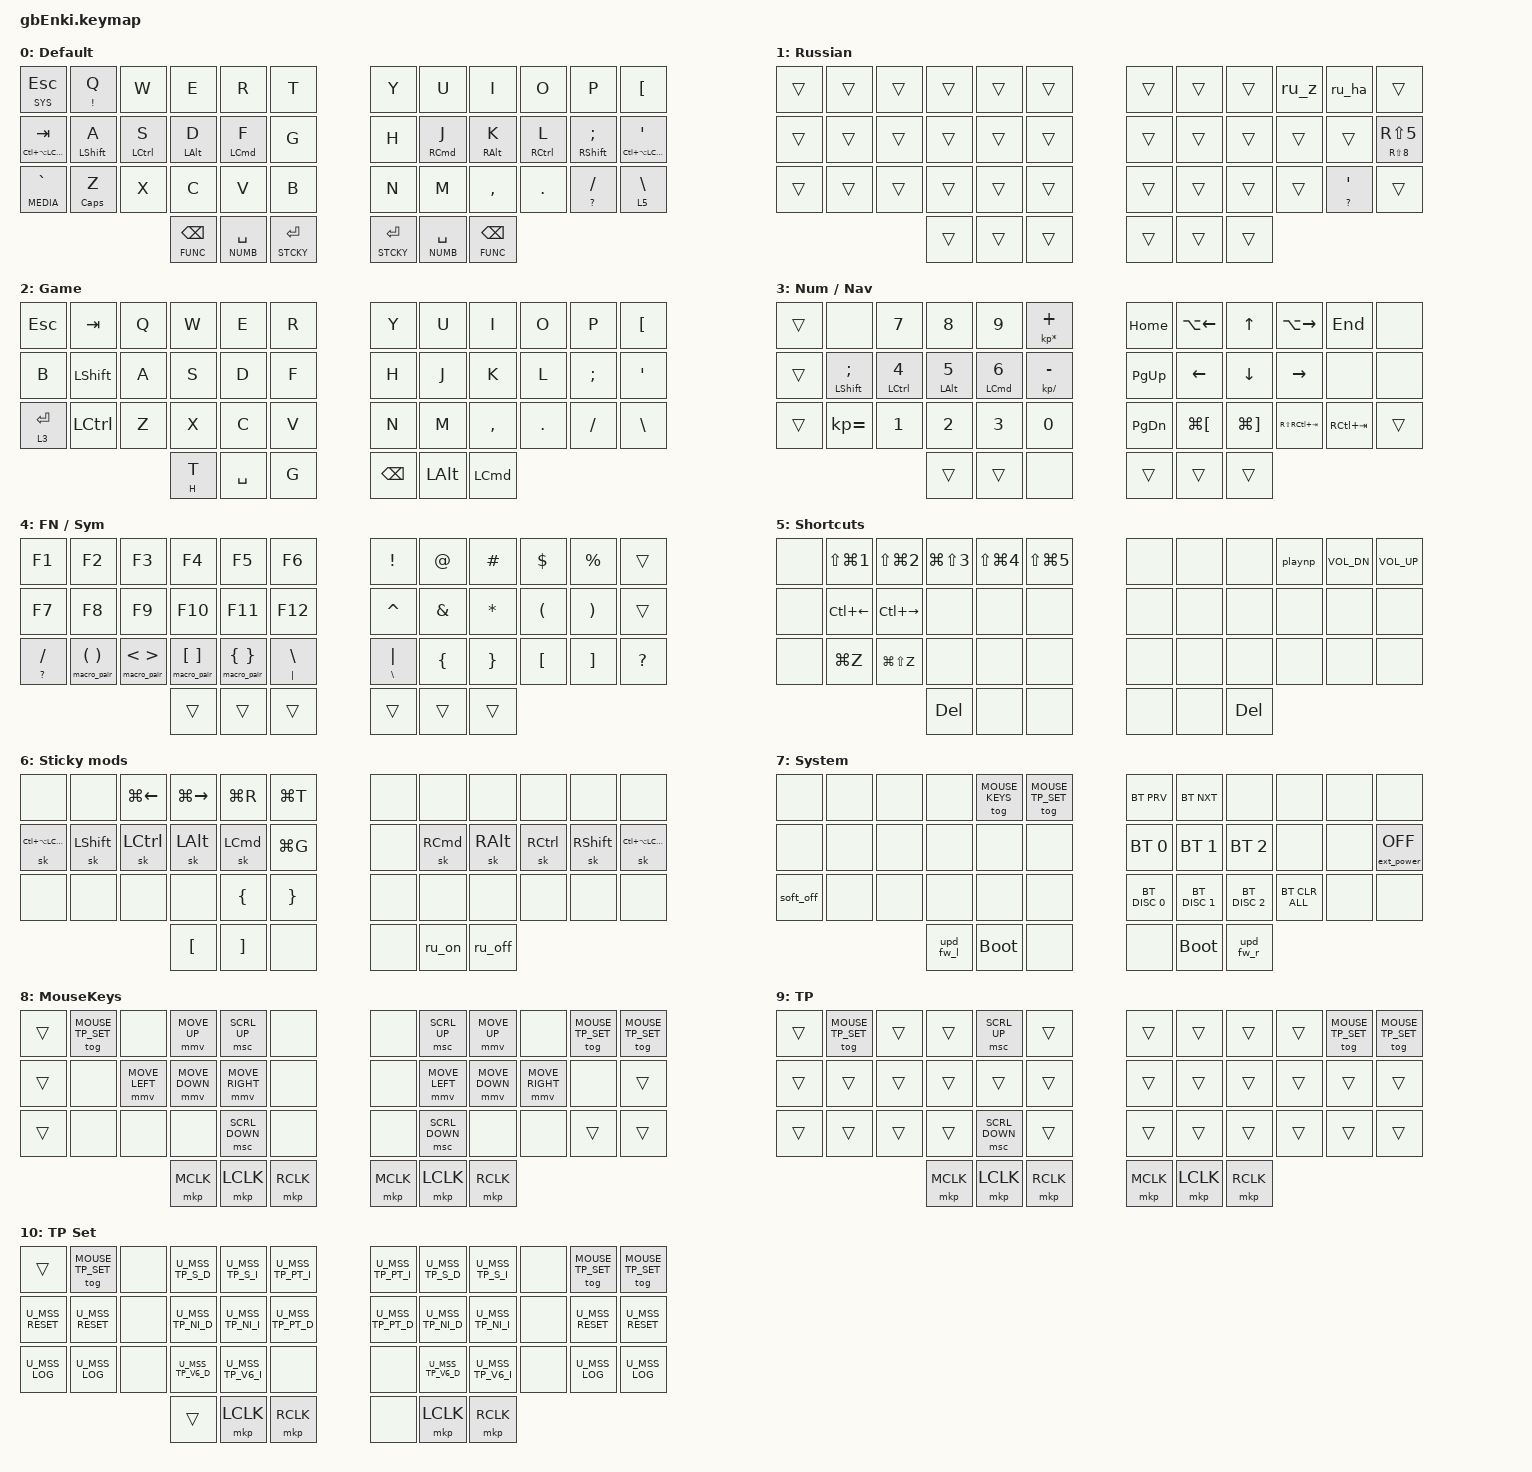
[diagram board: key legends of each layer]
/*
 * Copyright (c) 2020 The ZMK Contributors
 *
 * SPDX-License-Identifier: MIT
 */

// #include <behaviors/num_word.dtsi>
#include <behaviors.dtsi>
#include <dt-bindings/zmk/keys.h>
#include <dt-bindings/zmk/bt.h>
#include <dt-bindings/zmk/outputs.h>
#include <dt-bindings/zmk/ext_power.h>

#define DFLT   0
#define RU     1
#define GAME   2
#define NUMB   3
#define FUNC   4
#define MEDIA  5
#define STCKY  6
#define SYS    7
#define MOUSE_KEYS 8
#define MOUSE_TP 9
#define MOUSE_TP_SET 10

#define HAS_MOUSE_KEYS
#define HAS_MOUSE_TP
// #define ADAPTIVE_KEYS
// #define LEADER_KEY

#ifdef HAS_MOUSE_KEYS
  #include <dt-bindings/zmk/mouse.h>
  #include <behaviors/mouse_keys.dtsi>
#endif  // HAS_MOUSE_KEYS

#ifdef HAS_MOUSE_TP
  // We store the trackpoint settings in a separate file
  // to make organization a little easier.
  #include "include/mouse_tp.dtsi"
#endif  // HAS_MOUSE_TP


// Adjust layer keys based on enabled features.
//
// This prevents build errors when we build the firmware
// without the mouse keys PR or the TP module.
#ifdef HAS_MOUSE_KEYS
  #define U_TOG_M_KEYS &tog MOUSE_KEYS
#else
  #define U_TOG_M_KEYS &none
#endif  // HAS_MOUSE_KEYS

#ifdef HAS_MOUSE_TP
  #define U_TOG_TP_SET &tog MOUSE_TP_SET
#else
  #define U_TOG_TP_SET &none
#endif  // HAS_MOUSE_TP


&lt { quick-tap-ms = <250>; };

&mt {
    hold-trigger-on-release;
    flavor = "balanced";
    quick-tap-ms = <250>;
};

&soft_off { hold-time-ms = <2000>; };

/ {
    chosen {
      // zmk,physical-layout = &default_layout;
      zephyr,console = &cdc_acm_uart;
    };

    combos {
        compatible = "zmk,combos";

        combo_toggle_game {
            bindings = <&tog 2>;
            key-positions = <35 24>;
            layers = <0 2 1>;
        };

        combo_leader_key {
            bindings = <&kp F13>;
            key-positions = <14 21>;
            layers = <0 1>;
            timeout-ms = <80>;
            require-prior-idle-ms = <120>;
        };

        combo_ha_sch {
            bindings = <&kp O>;
            key-positions = <8 9>;
            layers = <1>;
        };

        combo_harden_sign {
            bindings = <&kp RIGHT_BRACKET>;
            key-positions = <31 32>;
            layers = <1>;
        };

        combo_yo {
            bindings = <&kp BACKSLASH>;
            key-positions = <4 5>;
            layers = <1>;
        };

        combo_excl {
            bindings = <&mt LA(N1) LS(N1)>;
            key-positions = <1 13>;
            layers = <0 1>;
        };

        combo_at {
            bindings = <&mt LA(N2) LS(N2)>;
            key-positions = <2 14>;
            layers = <0 1>;
        };

        combo_hash {
            bindings = <&mt LA(N3) LS(N3)>;
            key-positions = <3 15>;
            layers = <0 1>;
        };

        combo_doll {
            bindings = <&mt LA(N4) LS(N4)>;
            key-positions = <4 16>;
            layers = <0 1>;
        };

        combo_percnt {
            bindings = <&mt LA(N5) LS(N5)>;
            key-positions = <17 5>;
            layers = <0 1>;
        };

        combo_caret {
            bindings = <&mt LA(N6) LS(N6)>;
            key-positions = <6 18>;
            layers = <0 1>;
        };

        combo_ampersand {
            bindings = <&mt LA(N7) LS(N7)>;
            key-positions = <7 19>;
            layers = <0 1>;
        };

        combo_asterisk {
            bindings = <&mt LA(N8) LS(N8)>;
            key-positions = <8 20>;
            layers = <0 1>;
        };

        combo_lpar {
            bindings = <&mt LA(N9) LS(N9)>;
            key-positions = <9 21>;
            layers = <0 1>;
        };

        combo_rpar {
            bindings = <&mt LA(N0) LS(N0)>;
            key-positions = <10 22>;
            layers = <0 1>;
        };

        combo_under_ellipsis {
            bindings = <&mt LA(SEMI) LS(MINUS)>;
            key-positions = <8 7>;
            layers = <0 1>;
        };

        combo_equal {
            bindings = <&mt PLUS EQUAL>;
            key-positions = <18 19>;
            require-prior-idle-ms = <180>;
            layers = <0 1>;
        };

        combo_dash {
            bindings = <&mt LA(LS(MINUS)) MINUS>;
            key-positions = <20 19>;
            require-prior-idle-ms = <180>;
            layers = <0 1>;
        };

        combo_quo {
            bindings = <&single_double SQT SQT>;
            key-positions = <32 31>;
            layers = <0>;
        };

        combo_dquo {
            bindings = <&single_double DQT DQT>;
            key-positions = <32 33>;
            layers = <0>;
        };

        combo_dquo_ru {
            bindings = <&single_double LS(NUMBER_2) LS(NUMBER_2)>;
            key-positions = <32 33>;
            layers = <1>;
        };

        combo_grave {
            bindings = <&single_double GRAVE GRAVE>;
            key-positions = <33 34>;
            layers = <0>;
        };

        combo_del {
            bindings = <&mt LA(DEL) DEL>;
            key-positions = <8 9>;
            layers = <3>;
        };

        combo_bsp {
            bindings = <&mt LA(BSPC) BSPC>;
            key-positions = <7 8>;
            layers = <3>;
        };

        combo_mute {
            bindings = <&kp C_MUTE>;
            key-positions = <11 10>;
            layers = <5>;
        };

        combo_copy_cut {
            bindings = <&mt LG(X) LG(C)>;
            key-positions = <2 3>;
            layers = <0 1>;
        };

        combo_paste {
            bindings = <&mt LA(LC(V)) LG(V)>;
            key-positions = <3 4>;
            layers = <0 1>;
        };

        combo_html_tag {
            bindings = <&html_tag 0 0>;
            key-positions = <16 17>;
            layers = <0 1>;
        };

        combo_eq_quo {
            bindings = <&equals_qoute>;
            key-positions = <28 29>;
            layers = <0>;
        };

        combo_fr_quo {
            bindings = <&macro_pair LS(LA(EQUAL)) LA(EQUAL)>;
            key-positions = <28 29>;
            layers = <1>;
        };

        combo_sk_lshift {
            bindings = <&sk LSHFT>;
            key-positions = <13 26>;
            layers = <0 1>;
        };

        combo_sk_rshift {
            bindings = <&sk RSHFT>;
            key-positions = <33 22>;
            layers = <0 1>;
        };

        combo_par {
            bindings = <&par>;
            key-positions = <25 26>;
            layers = <3>;
        };

        combo_bkt {
            bindings = <&bkt>;
            key-positions = <26 27>;
            layers = <3>;
        };

        combo_brc {
            bindings = <&brc>;
            key-positions = <27 28>;
            layers = <3>;
        };

        combo_comma {
            bindings = <&mt SEMI COMMA>;
            key-positions = <26 27>;
            layers = <0>;
        };

        combo_comma_ru {
            bindings = <&mt RS(NUMBER_8) RS(NUMBER_6)>;
            key-positions = <26 27>;
            layers = <1>;
        };

        combo_dot {
            bindings = <&mt COLON DOT>;
            key-positions = <27 28>;
            layers = <0>;
        };

        combo_dot_ru {
            bindings = <&mt RS(NUMBER_5) RS(NUMBER_7)>;
            key-positions = <28 27>;
            layers = <1>;
        };

        combo_fwslash_question {
            bindings = <&kp SLASH>;
            key-positions = <33 34>;
            layers = <1>;
        };

        combo_ru_on {
            bindings = <&ru_on>;
            key-positions = <15 14 16>;
            layers = <1 0>;
        };

        combo_ru_off {
            bindings = <&ru_off>;
            key-positions = <27 26 28>;
            layers = <1 0>;
        };

        #ifdef ADAPTIVE_KEYS
        leader-key {
            bindings = <&ak_leader>;
            key-positions = <25 26>;
            layers = <1 0>;
        };
        #endif
    };

    macros {
        #include "lk_macros.dtsi"

        upd_fw_l: upd_fw {
            compatible = "zmk,behavior-macro";
            #binding-cells = <0>;
            bindings = <&kp LG(LC(LA(LS(NUMBER_1)))) &bootloader>;
        };

        upd_fw_r: upd_fw_r {
            compatible = "zmk,behavior-macro";
            #binding-cells = <0>;
            bindings = <&kp LG(LC(LA(LS(NUMBER_2)))) &bootloader>;
        };

        equals_qoute: equals_qoute {
            compatible = "zmk,behavior-macro";
            #binding-cells = <0>;
            bindings = <&kp EQUAL &kp DOUBLE_QUOTES &kp DOUBLE_QUOTES &kp LEFT>;
        };

        par: par {
            compatible = "zmk,behavior-macro";
            #binding-cells = <0>;
            bindings = <&kp LPAR &kp RPAR &kp LEFT>;
            tap-ms = <50>;
        };

        bkt: bkt {
            compatible = "zmk,behavior-macro";
            #binding-cells = <0>;
            bindings =
                <&macro_wait_time 50>,
                <&ru_off>,
                <&macro_wait_time 10>,
                <&kp LBKT &kp RBKT &kp LEFT>;

            label = "BKT";
        };

        brc: brc {
            compatible = "zmk,behavior-macro";
            #binding-cells = <0>;
            bindings =
                <&macro_wait_time 50>,
                <&ru_off>,
                <&macro_wait_time 10>,
                <&kp LBRC &kp RBRC &kp LEFT>;
        };

        ru_on: to_ru {
            compatible = "zmk,behavior-macro";
            #binding-cells = <0>;
            bindings = <&tog 1 &kp LS(LA(LC(LG(N))))>;
        };

        ru_off: to_en {
            compatible = "zmk,behavior-macro";
            #binding-cells = <0>;
            bindings = <&tog 1 &kp LS(LA(LC(LG(M))))>;
        };

        tag_open: html_tag_open {
            compatible = "zmk,behavior-macro";
            #binding-cells = <0>;
            bindings =
                <&macro_wait_time 50>,
                <&ru_off>,
                <&macro_wait_time 10>,
                <&kp LESS_THAN &kp GREATER_THAN &kp LEFT>;

            label = "HTML_TAG_OPEN";
        };

        tag_close: html_tag {
            compatible = "zmk,behavior-macro";
            #binding-cells = <0>;
            bindings =
                <&ru_off>,
                <&macro_wait_time 10>,
                <&kp LESS_THAN &kp GREATER_THAN &kp LEFT &kp SLASH>;
        };

        macro_double: macro_double {
            compatible = "zmk,behavior-macro-one-param";
            #binding-cells = <1>;
            bindings = <&macro_param_1to1 &kp MACRO_PLACEHOLDER &macro_param_1to1 &kp MACRO_PLACEHOLDER &kp LEFT>;
            label = "PARAMETRIC_PAIR";
        };

        macro_pair: macro_pair {
            compatible = "zmk,behavior-macro-two-param";
            #binding-cells = <2>;
            bindings =
                <&macro_param_1to1 &kp MACRO_PLACEHOLDER>,
                <&macro_press>,
                <&macro_param_2to1 &hold_sym_left MACRO_PLACEHOLDER 0>,
                <&macro_pause_for_release>,
                <&macro_release>,
                <&macro_param_2to1 &hold_sym_left MACRO_PLACEHOLDER 0>,
                <&macro_tap>;

            label = "MACRO_P";
        };

        sym_left: sym_left {
            compatible = "zmk,behavior-macro-one-param";
            #binding-cells = <1>;
            bindings = <&macro_param_1to1 &kp MACRO_PLACEHOLDER &kp LEFT>;
            label = "sym_left";
        };
    };

    behaviors {
        /omit-if-no-ref/

        #ifdef LEADER_KEY
        leader1: leader1 {
            compatible = "zmk,behavior-leader-key";
            #binding-cells = <0>;

            ba {
                sequence = <B A>;
                bindings = <&ba>;
            };

            bp {
                sequence = <B P>;
                bindings = <&bp>;
            };

            fs {
                sequence = <F S>;
                bindings = <&fs>;
            };

            fw {
                sequence = <F W>;
                bindings = <&fw>;
            };

            va {
                sequence = <V A>;
                bindings = <&va>;
            };

            ca {
                sequence = <C A>;
                bindings = <&ca>;
            };

            fd {
                sequence = <F D>;
                bindings = <&fd>;
            };

            me {
                sequence = <M E>;
                bindings = <&me>;
            };

            mw {
                sequence = <M W>;
                bindings = <&mw>;
            };

            nw {
                sequence = <N W>;
                bindings = <&nw>;
            };

            cs {
                sequence = <C S>;
                bindings = <&cs>;
            };

            st {
                sequence = <S T>;
                bindings = <&st>;
            };
        };
        #endif

        #ifdef ADAPTIVE_KEYS
        ak_leader: ak_leader {
            compatible = "zmk,behavior-adaptive-key";
            #binding-cells = <0>;
            bindings = <&leader1>;

            akt_s {
                trigger-keys = <S>;
                max-prior-idle-ms = <500>;
                bindings = <&kp H &kp U &kp S &kp H &kp A &kp K &kp O &kp V &kp AT &kp G &kp M &kp A &kp I &kp L &kp DOT &kp C &kp O &kp M>;
            };
        };
        #endif

        playnp: play_next_previous_media {
            compatible = "zmk,behavior-tap-dance";
            #binding-cells = <0>;
            tapping-term-ms = <300>;
            bindings = <&kp C_PP>, <&kp C_NEXT>, <&kp C_PREV>;
        };

        mtl: home-row-mods-left {
            compatible = "zmk,behavior-hold-tap";
            bindings = <&kp>, <&kp>;

            #binding-cells = <2>;
            tapping-term-ms = <200>;
            quick-tap-ms = <180>;
            flavor = "balanced";
            hold-trigger-on-release;
            hold-trigger-key-positions = <6 7 8 9 10 11 18 19 20 21 22 23 30 31 32 33 34 35 40 41 39 38 37 36 12 24>;
        };

        mtr: home-row-mods-right {
            compatible = "zmk,behavior-hold-tap";
            bindings = <&kp>, <&kp>;

            #binding-cells = <2>;
            tapping-term-ms = <200>;
            quick-tap-ms = <180>;
            flavor = "balanced";
            hold-trigger-on-release;
            hold-trigger-key-positions = <0 1 2 3 4 5 12 13 14 15 16 17 24 25 26 27 28 29 36 37 38 39 40 41>;
        };

        tog_on: toggle_layer_on_only {
            compatible = "zmk,behavior-toggle-layer";
            #binding-cells = <1>;
            display-name = "Toggle Layer On";
            toggle-mode = "on";
        };

        tog_off: toggle_layer_off_only {
            compatible = "zmk,behavior-toggle-layer";
            #binding-cells = <1>;
            display-name = "Toggle Layer Off";
            toggle-mode = "off";
        };

        html_tag: html_tag {
            compatible = "zmk,behavior-hold-tap";
            label = "HTML_TAG";
            bindings = <&tag_close>, <&tag_open>;

            #binding-cells = <2>;
            tapping-term-ms = <200>;
            flavor = "balanced";
        };

        single_double: single_double {
            compatible = "zmk,behavior-hold-tap";
            label = "SINGLE_DOUBLE";
            bindings = <&macro_double>, <&kp>;

            #binding-cells = <2>;
            flavor = "tap-preferred";
            tapping-term-ms = <200>;
        };

        hold_sym_left: hold_sym_left {
            compatible = "zmk,behavior-hold-tap";
            label = "HOLD_SYM_LEFT";
            bindings = <&sym_left>, <&none>;

            #binding-cells = <2>;
            flavor = "tap-preferred";
            tapping-term-ms = <200>;
        };

        ru_z: ru_z {
            compatible = "zmk,behavior-mod-morph";
            label = "RU_Z";
            bindings = <&kp P>, <&kp O>;

            #binding-cells = <0>;
            mods = <(MOD_LCTL|MOD_LALT|MOD_LGUI|MOD_RCTL|MOD_RALT|MOD_RGUI)>;
            keep-mods = <(MOD_LCTL|MOD_LALT|MOD_LGUI|MOD_RCTL|MOD_RALT|MOD_RGUI)>;
        };

        ru_ha: ru_ha {
            compatible = "zmk,behavior-mod-morph";
            label = "RU_HA";
            bindings = <&kp LEFT_BRACKET>, <&kp P>;

            #binding-cells = <0>;
            mods = <(MOD_LCTL|MOD_LALT|MOD_LGUI|MOD_RCTL|MOD_RALT|MOD_RGUI)>;
            keep-mods = <(MOD_LCTL|MOD_LALT|MOD_LGUI|MOD_RCTL|MOD_RALT|MOD_RGUI)>;
        };
    };

    keymap {
        compatible = "zmk,keymap";

        default_layer {
            display-name = "Default";
            bindings = <
//    ┌─────────────────────────┬───────────┬────────────┬────────────┬──────────────┬─────────────┐                                 ┌─────────────┬──────────────┬────────────┬────────────┬────────────┬───────────────────────┐
//    │       lt SYS esc        │  mt ! Q   │     W      │     E      │      R       │      T      │                                 │      Y      │      U       │     I      │     O      │     P      │           [           │
//    ├─────────────────────────┼───────────┼────────────┼────────────┼──────────────┼─────────────┤                                 ├─────────────┼──────────────┼────────────┼────────────┼────────────┼───────────────────────┤
//    │ mt lctl(lalt(lgui)) tab │ mt lsft A │ mtl lctl S │ mtl lalt D │  mtl lgui F  │      G      │                                 │      H      │  mtr rgui J  │ mtr ralt K │ mtr rctl L │ mtr rsft ; │ mt lctl(lalt(lgui)) ' │
//    ├─────────────────────────┼───────────┼────────────┼────────────┼──────────────┼─────────────┤                                 ├─────────────┼──────────────┼────────────┼────────────┼────────────┼───────────────────────┤
//    │       lt MEDIA `        │ mt caps Z │     X      │     C      │      V       │      B      │                                 │      N      │      M       │     ,      │     .      │   mt ? /   │        lt 5 \         │
//    └─────────────────────────┴───────────┴────────────┴────────────┼──────────────┼─────────────┼──────────────┐   ┌──────────────┼─────────────┼──────────────┼────────────┴────────────┴────────────┴───────────────────────┘
//                                                                    │ lt FUNC bspc │ lt NUMB spc │ lt STCKY ent │   │ lt STCKY ent │ lt NUMB spc │ lt FUNC bspc │
//                                                                    └──────────────┴─────────────┴──────────────┘   └──────────────┴─────────────┴──────────────┘
  &lt SYS ESC            &mt EXCL Q     &kp W          &kp E         &kp R           &kp T                                                    &kp Y            &kp U           &kp I         &kp O          &kp P              &kp LBKT
  &mt LC(LA(LCMD)) TAB   &mt LSHIFT A   &mtl LCTRL S   &mtl LALT D   &mtl LCMD F     &kp G                                                    &kp H            &mtr RCMD J     &mtr RALT K   &mtr RCTRL L   &mtr RSHIFT SEMI   &mt LC(LA(LCMD)) SQT
  &lt MEDIA GRAVE        &mt CAPS Z     &kp X          &kp C         &kp V           &kp B                                                    &kp N            &kp M           &kp COMMA     &kp DOT        &mt QMARK SLASH    &lt 5 BSLH
                                                                     &lt FUNC BSPC   &lt NUMB SPACE   &lt STCKY ENTER       &lt STCKY ENTER   &lt NUMB SPACE   &lt FUNC BSPC
            >;
        };

        ru {
            display-name = "Russian";
            bindings = <
//    ┌─────┬─────┬─────┬─────┬─────┬─────┐               ┌─────┬─────┬─────┬───────┬────────┬────────────────────┐
//    │     │     │     │     │     │     │               │     │     │     │ &ru_z │ &ru_ha │                    │
//    ├─────┼─────┼─────┼─────┼─────┼─────┤               ├─────┼─────┼─────┼───────┼────────┼────────────────────┤
//    │     │     │     │     │     │     │               │     │     │     │       │        │ mt rsft(8) rsft(5) │
//    ├─────┼─────┼─────┼─────┼─────┼─────┤               ├─────┼─────┼─────┼───────┼────────┼────────────────────┤
//    │     │     │     │     │     │     │               │     │     │     │       │ mt ? ' │                    │
//    └─────┴─────┴─────┴─────┼─────┼─────┼─────┐   ┌─────┼─────┼─────┼─────┴───────┴────────┴────────────────────┘
//                            │     │     │     │   │     │     │     │
//                            └─────┴─────┴─────┘   └─────┴─────┴─────┘
  &trans   &trans   &trans   &trans   &trans   &trans                         &trans   &trans   &trans   &ru_z    &ru_ha           &trans
  &trans   &trans   &trans   &trans   &trans   &trans                         &trans   &trans   &trans   &trans   &trans           &mt RS(NUMBER_8) RS(NUMBER_5)
  &trans   &trans   &trans   &trans   &trans   &trans                         &trans   &trans   &trans   &trans   &mt QMARK APOS   &trans
                                      &trans   &trans   &trans       &trans   &trans   &trans
            >;
        };

        game {
            display-name = "Game";
            bindings = <
//    ┌──────────┬──────┬───┬───┬────────┬─────┐              ┌──────┬──────┬───┬───┬───┬───┐
//    │   esc    │ tab  │ Q │ W │   E    │  R  │              │  Y   │  U   │ I │ O │ P │ [ │
//    ├──────────┼──────┼───┼───┼────────┼─────┤              ├──────┼──────┼───┼───┼───┼───┤
//    │    B     │ lsft │ A │ S │   D    │  F  │              │  H   │  J   │ K │ L │ ; │ ' │
//    ├──────────┼──────┼───┼───┼────────┼─────┤              ├──────┼──────┼───┼───┼───┼───┤
//    │ lt 3 ent │ lctl │ Z │ X │   C    │  V  │              │  N   │  M   │ , │ . │ / │ \ │
//    └──────────┴──────┴───┴───┼────────┼─────┼───┐   ┌──────┼──────┼──────┼───┴───┴───┴───┘
//                              │ mt H T │ spc │ G │   │ bspc │ lalt │ lgui │
//                              └────────┴─────┴───┘   └──────┴──────┴──────┘
  &kp ESC       &kp TAB     &kp Q   &kp W   &kp E     &kp R                              &kp Y      &kp U      &kp I       &kp O     &kp P      &kp LBKT
  &kp B         &kp LSHFT   &kp A   &kp S   &kp D     &kp F                              &kp H      &kp J      &kp K       &kp L     &kp SEMI   &kp SQT
  &lt 3 ENTER   &kp LCTRL   &kp Z   &kp X   &kp C     &kp V                              &kp N      &kp M      &kp COMMA   &kp DOT   &kp FSLH   &kp BSLH
                                            &mt H T   &kp SPACE   &kp G       &kp BSPC   &kp LALT   &kp LCMD
            >;
        };

        num {
            display-name = "Num / Nav";
            bindings = <
//    ┌─────┬───────────┬───────────┬───────────┬───────────┬───────────┐               ┌──────┬────────────┬─────────┬─────────────────┬───────────┬─────┐
//    │     │           │     7     │     8     │     9     │ mt kp_* + │               │ home │ lalt(left) │   up    │   lalt(rght)    │    end    │     │
//    ├─────┼───────────┼───────────┼───────────┼───────────┼───────────┤               ├──────┼────────────┼─────────┼─────────────────┼───────────┼─────┤
//    │     │ mt lsft ; │ mt lctl 4 │ mt lalt 5 │ mt lgui 6 │ mt kp_/ - │               │ pgup │    left    │  down   │      rght       │           │     │
//    ├─────┼───────────┼───────────┼───────────┼───────────┼───────────┤               ├──────┼────────────┼─────────┼─────────────────┼───────────┼─────┤
//    │     │   kp_=    │     1     │     2     │     3     │     0     │               │ pgdn │  lgui([)   │ lgui(]) │ rsft(rctl(tab)) │ rctl(tab) │     │
//    └─────┴───────────┴───────────┴───────────┼───────────┼───────────┼─────┐   ┌─────┼──────┼────────────┼─────────┴─────────────────┴───────────┴─────┘
//                                              │           │           │     │   │     │      │            │
//                                              └───────────┴───────────┴─────┘   └─────┴──────┴────────────┘
  &trans   &none             &kp N7         &kp N8        &kp N9        &mt KP_ASTERISK PLUS                        &kp HOME    &kp LA(LEFT)   &kp UP         &kp LA(RIGHT)     &kp END       &none
  &trans   &mt LSHIFT SEMI   &mt LCTRL N4   &mt LALT N5   &mt LCMD N6   &mt KP_DIVIDE MINUS                         &kp PG_UP   &kp LEFT       &kp DOWN       &kp RIGHT         &none         &none
  &trans   &kp KP_EQUAL      &kp N1         &kp N2        &kp N3        &kp N0                                      &kp PG_DN   &kp LG(LBKT)   &kp LG(RBKT)   &kp RS(RC(TAB))   &kp RC(TAB)   &trans
                                                          &trans        &trans                 &none       &trans   &trans      &trans
            >;
        };

        symb {
            display-name = "FN / Sym";
            bindings = <
//    ┌────────┬─────────────────┬─────────────────┬─────────────────┬─────────────────┬────────┐               ┌────────┬─────┬───┬───┬───┬─────┐
//    │   f1   │       f2        │       f3        │       f4        │       f5        │   f6   │               │   !    │  @  │ # │ $ │ % │     │
//    ├────────┼─────────────────┼─────────────────┼─────────────────┼─────────────────┼────────┤               ├────────┼─────┼───┼───┼───┼─────┤
//    │   f7   │       f8        │       f9        │       f10       │       f11       │  f12   │               │   ^    │  &  │ * │ ( │ ) │     │
//    ├────────┼─────────────────┼─────────────────┼─────────────────┼─────────────────┼────────┤               ├────────┼─────┼───┼───┼───┼─────┤
//    │ mt ? / │ &macro_pair ( ) │ &macro_pair < > │ &macro_pair [ ] │ &macro_pair { } │ mt | \ │               │ mt \ | │  {  │ } │ [ │ ] │  ?  │
//    └────────┴─────────────────┴─────────────────┴─────────────────┼─────────────────┼────────┼─────┐   ┌─────┼────────┼─────┼───┴───┴───┴─────┘
//                                                                   │                 │        │     │   │     │        │     │
//                                                                   └─────────────────┴────────┴─────┘   └─────┴────────┴─────┘
  &kp F1            &kp F2                  &kp F3              &kp F4                  &kp F5                  &kp F6                                &kp EXCL        &kp AT     &kp POUND   &kp DLLR   &kp PERCENT   &trans
  &kp F7            &kp F8                  &kp F9              &kp F10                 &kp F11                 &kp F12                               &kp CARET       &kp AMPS   &kp ASTRK   &kp LPAR   &kp RPAR      &trans
  &mt QMARK SLASH   &macro_pair LPAR RPAR   &macro_pair LT GT   &macro_pair LBKT RBKT   &macro_pair LBRC RBRC   &mt PIPE BSLH                         &mt BSLH PIPE   &kp LBRC   &kp RBRC    &kp LBKT   &kp RBKT      &kp QMARK
                                                                                        &trans                  &trans          &trans       &trans   &trans          &trans
            >;
        };

        media {
            display-name = "Shortcuts";
            bindings = <
//    ┌─────┬───────────────┬───────────────┬───────────────┬───────────────┬───────────────┐               ┌─────┬─────┬─────┬─────────┬──────┬──────┐
//    │     │ lsft(lgui(1)) │ lsft(lgui(2)) │ lgui(lsft(3)) │ lsft(lgui(4)) │ lsft(lgui(5)) │               │     │     │     │ &playnp │ vold │ volu │
//    ├─────┼───────────────┼───────────────┼───────────────┼───────────────┼───────────────┤               ├─────┼─────┼─────┼─────────┼──────┼──────┤
//    │     │  lctl(left)   │  lctl(rght)   │               │               │               │               │     │     │     │         │      │      │
//    ├─────┼───────────────┼───────────────┼───────────────┼───────────────┼───────────────┤               ├─────┼─────┼─────┼─────────┼──────┼──────┤
//    │     │    lgui(Z)    │ lgui(lsft(Z)) │               │               │               │               │     │     │     │         │      │      │
//    └─────┴───────────────┴───────────────┴───────────────┼───────────────┼───────────────┼─────┐   ┌─────┼─────┼─────┼─────┴─────────┴──────┴──────┘
//                                                          │      del      │               │     │   │     │     │ del │
//                                                          └───────────────┴───────────────┴─────┘   └─────┴─────┴─────┘
  &none   &kp LS(LG(N1))   &kp LS(LG(N2))   &kp LG(LS(N3))   &kp LS(LG(N4))   &kp LS(LG(N5))                       &none   &none     &none   &playnp   &kp C_VOL_DN   &kp C_VOL_UP
  &none   &kp LC(LEFT)     &kp LC(RIGHT)    &none            &none            &none                                &none   &none     &none   &none     &none          &none
  &none   &kp LG(Z)        &kp LG(LS(Z))    &none            &none            &none                                &none   &none     &none   &none     &none          &none
                                                             &kp DEL          &none            &none       &none   &none   &kp DEL
            >;
        };

        sticky {
            display-name = "Sticky mods";
            bindings = <
//    ┌──────────────────────┬──────────┬────────────┬────────────┬──────────┬─────────┐               ┌────────┬──────────┬──────────┬──────────┬──────────┬──────────────────────┐
//    │                      │          │ lgui(left) │ lgui(rght) │ lgui(R)  │ lgui(T) │               │        │          │          │          │          │                      │
//    ├──────────────────────┼──────────┼────────────┼────────────┼──────────┼─────────┤               ├────────┼──────────┼──────────┼──────────┼──────────┼──────────────────────┤
//    │ &sk lctl(lalt(lgui)) │ &sk lsft │  &sk lctl  │  &sk lalt  │ &sk lgui │ lgui(G) │               │        │ &sk rgui │ &sk ralt │ &sk rctl │ &sk rsft │ &sk lctl(lalt(lgui)) │
//    ├──────────────────────┼──────────┼────────────┼────────────┼──────────┼─────────┤               ├────────┼──────────┼──────────┼──────────┼──────────┼──────────────────────┤
//    │                      │          │            │            │    {     │    }    │               │        │          │          │          │          │                      │
//    └──────────────────────┴──────────┴────────────┴────────────┼──────────┼─────────┼─────┐   ┌─────┼────────┼──────────┼──────────┴──────────┴──────────┴──────────────────────┘
//                                                                │    [     │    ]    │     │   │     │ &ru_on │ &ru_off  │
//                                                                └──────────┴─────────┴─────┘   └─────┴────────┴──────────┘
  &none              &none        &kp LG(LEFT)   &kp LG(RIGHT)   &kp LG(R)   &kp LG(T)                       &none    &none      &none      &none       &none        &none
  &sk LC(LA(LCMD))   &sk LSHIFT   &sk LCTRL      &sk LALT        &sk LCMD    &kp LG(G)                       &none    &sk RCMD   &sk RALT   &sk RCTRL   &sk RSHIFT   &sk LC(LA(LCMD))
  &none              &none        &none          &none           &kp LBRC    &kp RBRC                        &none    &none      &none      &none       &none        &none
                                                                 &kp LBKT    &kp RBKT    &none       &none   &ru_on   &ru_off
            >;
        };

        system {
            display-name = "System";
            bindings = <
//    ┌───────────┬─────┬─────┬─────┬───────────┬──────┐               ┌──────────────┬──────────────┬──────────────┬────────────┬─────┬────────────────┐
//    │           │     │     │     │  M_KEYS   │TP_SET│               │    bt_prv    │    bt_nxt    │              │            │     │                │
//    ├───────────┼─────┼─────┼─────┼───────────┼──────┤               ├──────────────┼──────────────┼──────────────┼────────────┼─────┼────────────────┤
//    │           │     │     │     │           │      │               │   bt_sel 0   │   bt_sel 1   │   bt_sel 2   │            │     │    epwr_ on    │
//    ├───────────┼─────┼─────┼─────┼───────────┼──────┤               ├──────────────┼──────────────┼──────────────┼────────────┼─────┼────────────────┤
//    │ &soft_off │     │     │     │           │      │               │ bt_BT_DISC 0 │ bt_BT_DISC 1 │ bt_BT_DISC 2 │ bt_clr_ALL │     │ &studio_unlock │
//    └───────────┴─────┴─────┴─────┼───────────┼──────┼─────┐   ┌─────┼──────────────┼──────────────┼──────────────┴────────────┴─────┴────────────────┘
//                                  │ &upd_fw_l │ boot │     │   │     │     boot     │  &upd_fw_r   │
//                                  └───────────┴──────┴─────┘   └─────┴──────────────┴──────────────┘
  &none       &none   &none   &none   U_TOG_M_KEYS  U_TOG_TP_SET                     &bt BT_PRV      &bt BT_NXT      &none           &none            &none   &none
  &none       &none   &none   &none   &none        &none                             &bt BT_SEL 0    &bt BT_SEL 1    &bt BT_SEL 2    &none            &none   &ext_power EP_OFF
  &soft_off   &none   &none   &none   &none        &none                             &bt BT_DISC 0   &bt BT_DISC 1   &bt BT_DISC 2   &bt BT_CLR_ALL   &none   &none
                                      &upd_fw_l    &bootloader   &none       &none   &bootloader     &upd_fw_r
            >;
        };

        #ifdef HAS_MOUSE_KEYS

            MouseKeys_layer {
              display-name = "MouseKeys";
              bindings = <
        // ╭────────────────────────┬────────────────────────┬────────────────────────┬────────────────────────┬────────────────────────┬────────────────────────╮    ╭────────────────────────┬────────────────────────┬────────────────────────┬────────────────────────┬────────────────────────┬────────────────────────╮
             &trans                   U_TOG_TP_SET             &none                    &mmv MOVE_UP             &msc SCRL_UP             &none                         &none                    &msc SCRL_UP             &mmv MOVE_UP             &none                    U_TOG_TP_SET              U_TOG_TP_SET
        // ├────────────────────────┼────────────────────────┼────────────────────────┼────────────────────────┼────────────────────────┼────────────────────────┤    ├────────────────────────┼────────────────────────┼────────────────────────┼────────────────────────┼────────────────────────┼────────────────────────┤
             &trans                   &none                    &mmv MOVE_LEFT           &mmv MOVE_DOWN           &mmv MOVE_RIGHT          &none                         &none                    &mmv MOVE_LEFT           &mmv MOVE_DOWN           &mmv MOVE_RIGHT          &none                     &trans
        // ├────────────────────────┼────────────────────────┼────────────────────────┼────────────────────────┼────────────────────────┼────────────────────────┤    ├────────────────────────┼────────────────────────┼────────────────────────┼────────────────────────┼────────────────────────┼────────────────────────┤
             &trans                   &none                    &none                    &none                    &msc SCRL_DOWN           &none                         &none                    &msc SCRL_DOWN           &none                    &none                    &trans                    &trans
        // ╰────────────────────────┴────────────────────────┴────────────────────────┴────────────────────────┼────────────────────────┼────────────────────────┤    ├────────────────────────┼────────────────────────┼────────────────────────┼────────────────────────┴────────────────────────┼────────────────────────╯
                                                                                        &mkp MCLK                &mkp LCLK                &mkp RCLK                     &mkp MCLK                &mkp LCLK                &mkp RCLK
        //                                                                            ╰────────────────────────┴────────────────────────┴────────────────────────╯    ╰────────────────────────┴────────────────────────┴────────────────────────╯
              >;
            };

        #endif

        #ifdef HAS_MOUSE_TP

            // Automatically activated when the mouse or trackpoint moves.
            // Configured in `include/mouse_tp.dtsi`.
            MouseTP_layer {
              display-name = "TP";
              bindings = <
        // ╭────────────────────────┬────────────────────────┬────────────────────────┬────────────────────────┬────────────────────────┬────────────────────────╮    ╭────────────────────────┬────────────────────────┬────────────────────────┬────────────────────────┬────────────────────────┬────────────────────────╮
             &trans                   U_TOG_TP_SET             &trans                   &trans                   &msc SCRL_UP             &trans                        &trans                   &trans                   &trans                   &trans                   U_TOG_TP_SET              U_TOG_TP_SET
        // ├────────────────────────┼────────────────────────┼────────────────────────┼────────────────────────┼────────────────────────┼────────────────────────┤    ├────────────────────────┼────────────────────────┼────────────────────────┼────────────────────────┼────────────────────────┼────────────────────────┤
             &trans                   &trans                   &trans                   &trans                   &trans                   &trans                        &trans                   &trans                   &trans                   &trans                   &trans                    &trans
        // ├────────────────────────┼────────────────────────┼────────────────────────┼────────────────────────┼────────────────────────┼────────────────────────┤    ├────────────────────────┼────────────────────────┼────────────────────────┼────────────────────────┼────────────────────────┼────────────────────────┤
             &trans                   &trans                   &trans                   &trans                   &msc SCRL_DOWN           &trans                        &trans                   &trans                   &trans                   &trans                   &trans                    &trans
        // ╰────────────────────────┴────────────────────────┴────────────────────────┴────────────────────────┼────────────────────────┼────────────────────────┤    ├────────────────────────┼────────────────────────┼────────────────────────┼────────────────────────┴────────────────────────┼────────────────────────╯
                                                                                        &mkp MCLK                &mkp LCLK                &mkp RCLK                     &mkp MCLK                &mkp LCLK                &mkp RCLK
        //                                                                            ╰────────────────────────┴────────────────────────┴────────────────────────╯    ╰────────────────────────┴────────────────────────┴────────────────────────╯
              >;
            };

            // You can find the defines for the actual key press behaviors in `include/mouse_tp.dtsi`.
            MouseSettings_layer {
              display-name = "TP Set";
              bindings = <
        // ╭────────────────────────┬────────────────────────┬────────────────────────┬────────────────────────┬────────────────────────┬────────────────────────╮    ╭────────────────────────┬────────────────────────┬────────────────────────┬────────────────────────┬────────────────────────┬────────────────────────╮
             &trans                   U_TOG_TP_SET             &none                    U_MSS_TP_S_D             U_MSS_TP_S_I             U_MSS_TP_PT_I                 U_MSS_TP_PT_I            U_MSS_TP_S_D             U_MSS_TP_S_I             &none                    U_TOG_TP_SET              U_TOG_TP_SET
        // ├────────────────────────┼────────────────────────┼────────────────────────┼────────────────────────┼────────────────────────┼────────────────────────┤    ├────────────────────────┼────────────────────────┼────────────────────────┼────────────────────────┼────────────────────────┼────────────────────────┤
             U_MSS_RESET              U_MSS_RESET              &none                    U_MSS_TP_NI_D            U_MSS_TP_NI_I            U_MSS_TP_PT_D                 U_MSS_TP_PT_D            U_MSS_TP_NI_D            U_MSS_TP_NI_I            &none                    U_MSS_RESET               U_MSS_RESET
        // ├────────────────────────┼────────────────────────┼────────────────────────┼────────────────────────┼────────────────────────┼────────────────────────┤    ├────────────────────────┼────────────────────────┼────────────────────────┼────────────────────────┼────────────────────────┼────────────────────────┤
             U_MSS_LOG                U_MSS_LOG                &none                    U_MSS_TP_V6_D            U_MSS_TP_V6_I            &none                         &none                    U_MSS_TP_V6_D            U_MSS_TP_V6_I            &none                    U_MSS_LOG                 U_MSS_LOG
        // ╰────────────────────────┴────────────────────────┴────────────────────────┴────────────────────────┼────────────────────────┼────────────────────────┤    ├────────────────────────┼────────────────────────┼────────────────────────┼────────────────────────┴────────────────────────┼────────────────────────╯
                                                                                        &trans                   &mkp LCLK                &mkp RCLK                     &none                    &mkp LCLK                &mkp RCLK
        //                                                                            ╰────────────────────────┴────────────────────────┴────────────────────────╯    ╰────────────────────────┴────────────────────────┴────────────────────────╯
              >;
            };

        #endif
    };
};

// Allow USB logging
&usbd {
	status = "okay";
	cdc_acm_uart: cdc_acm_uart {
		compatible = "zephyr,cdc-acm-uart";
		label = "CDC_ACM_0";
	};
};
